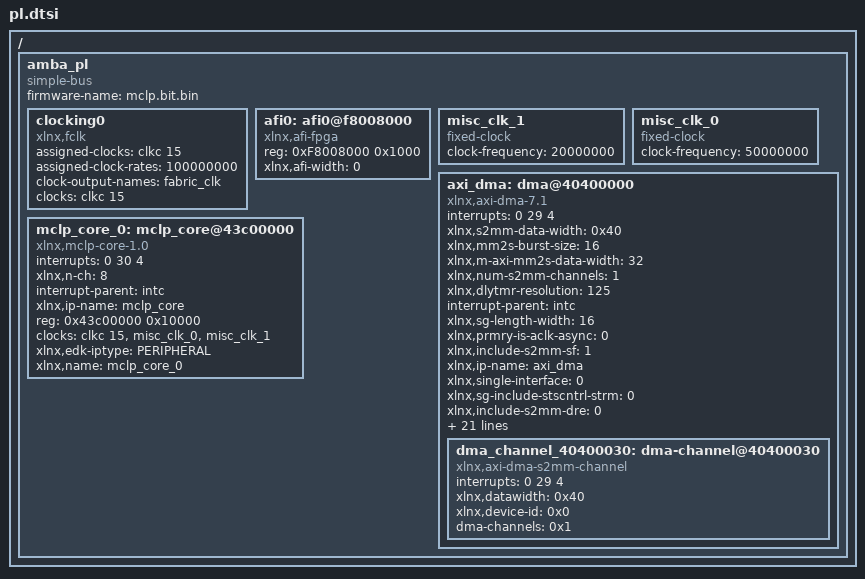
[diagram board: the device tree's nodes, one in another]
/ {
	amba_pl: amba_pl {
		ranges;
		compatible = "simple-bus";
		#address-cells = <1>;
		#size-cells = <1>;
		firmware-name = "mclp.bit.bin";
		clocking0: clocking0 {
			compatible = "xlnx,fclk";
			assigned-clocks = <&clkc 15>;
			assigned-clock-rates = <100000000>;
			#clock-cells = <0>;
			clock-output-names = "fabric_clk";
			clocks = <&clkc 15>;
		};
		afi0: afi0@f8008000 {
			status = "okay";
			compatible = "xlnx,afi-fpga";
			#address-cells = <1>;
			reg = <0xF8008000 0x1000>;
			#size-cells = <0>;
			xlnx,afi-width = <0>;
		};
		misc_clk_1: misc_clk_1 {
			compatible = "fixed-clock";
			clock-frequency = <20000000>;
			#clock-cells = <0>;
		};
		misc_clk_0: misc_clk_0 {
			compatible = "fixed-clock";
			clock-frequency = <50000000>;
			#clock-cells = <0>;
		};
		axi_dma: dma@40400000 {
			interrupts = < 0 29 4 >;
			compatible = "xlnx,axi-dma-7.1" , "xlnx,axi-dma-1.00.a";
			xlnx,s2mm-data-width = <0x40>;
			xlnx,mm2s-burst-size = <16>;
			xlnx,m-axi-mm2s-data-width = <32>;
			xlnx,num-s2mm-channels = <1>;
			xlnx,dlytmr-resolution = <125>;
			interrupt-parent = <&intc>;
			xlnx,sg-length-width = <16>;
			xlnx,prmry-is-aclk-async = <0>;
			xlnx,include-s2mm-sf = <1>;
			#dma-cells = <1>;
			xlnx,ip-name = "axi_dma";
			xlnx,single-interface = <0>;
			xlnx,sg-include-stscntrl-strm = <0>;
			xlnx,include-s2mm-dre = <0>;
			reg = <0x40400000 0x10000>;
			xlnx,addr-width = <32>;
			xlnx,include-s2mm = <1>;
			clocks = <&clkc 15>, <&clkc 15>, <&clkc 15>;
			xlnx,s-axis-s2mm-tdata-width = <64>;
			xlnx,micro-dma = <0>;
			xlnx,increase-throughput = <0>;
			xlnx,mm2s-data-width = <0x20>;
			xlnx,addrwidth = <0x20>;
			xlnx,include-sg;
			xlnx,sg-use-stsapp-length = <0>;
			xlnx,m-axis-mm2s-tdata-width = <32>;
			xlnx,edk-iptype = "PERIPHERAL";
			xlnx,s2mm-burst-size = <16>;
			xlnx,m-axi-s2mm-data-width = <64>;
			xlnx,num-mm2s-channels = <1>;
			xlnx,enable-multi-channel = <0>;
			status = "okay";
			xlnx,include-mm2s-sf = <1>;
			clock-names = "m_axi_s2mm_aclk" , "m_axi_sg_aclk" , "s_axi_lite_aclk";
			interrupt-names = "s2mm_introut";
			xlnx,include-mm2s = <0>;
			xlnx,include-mm2s-dre = <0>;
			xlnx,name = "axi_dma";
			dma_channel_40400030: dma-channel@40400030 {
				interrupts = <0 29 4>;
				xlnx,datawidth = <0x40>;
				xlnx,device-id = <0x0>;
				compatible = "xlnx,axi-dma-s2mm-channel";
				dma-channels = <0x1>;
			};
		};
		mclp_core_0: mclp_core@43c00000 {
			compatible = "xlnx,mclp-core-1.0";
			interrupts = < 0 30 4 >;
			xlnx,n-ch = <8>;
			interrupt-parent = <&intc>;
			xlnx,ip-name = "mclp_core";
			reg = <0x43c00000 0x10000>;
			clocks = <&clkc 15>, <&misc_clk_0>, <&misc_clk_1>;
			xlnx,edk-iptype = "PERIPHERAL";
			status = "okay";
			clock-names = "aclk" , "clk_dsp" , "clk_spi";
			interrupt-names = "irq";
			xlnx,name = "mclp_core_0";
		};
	};
};
